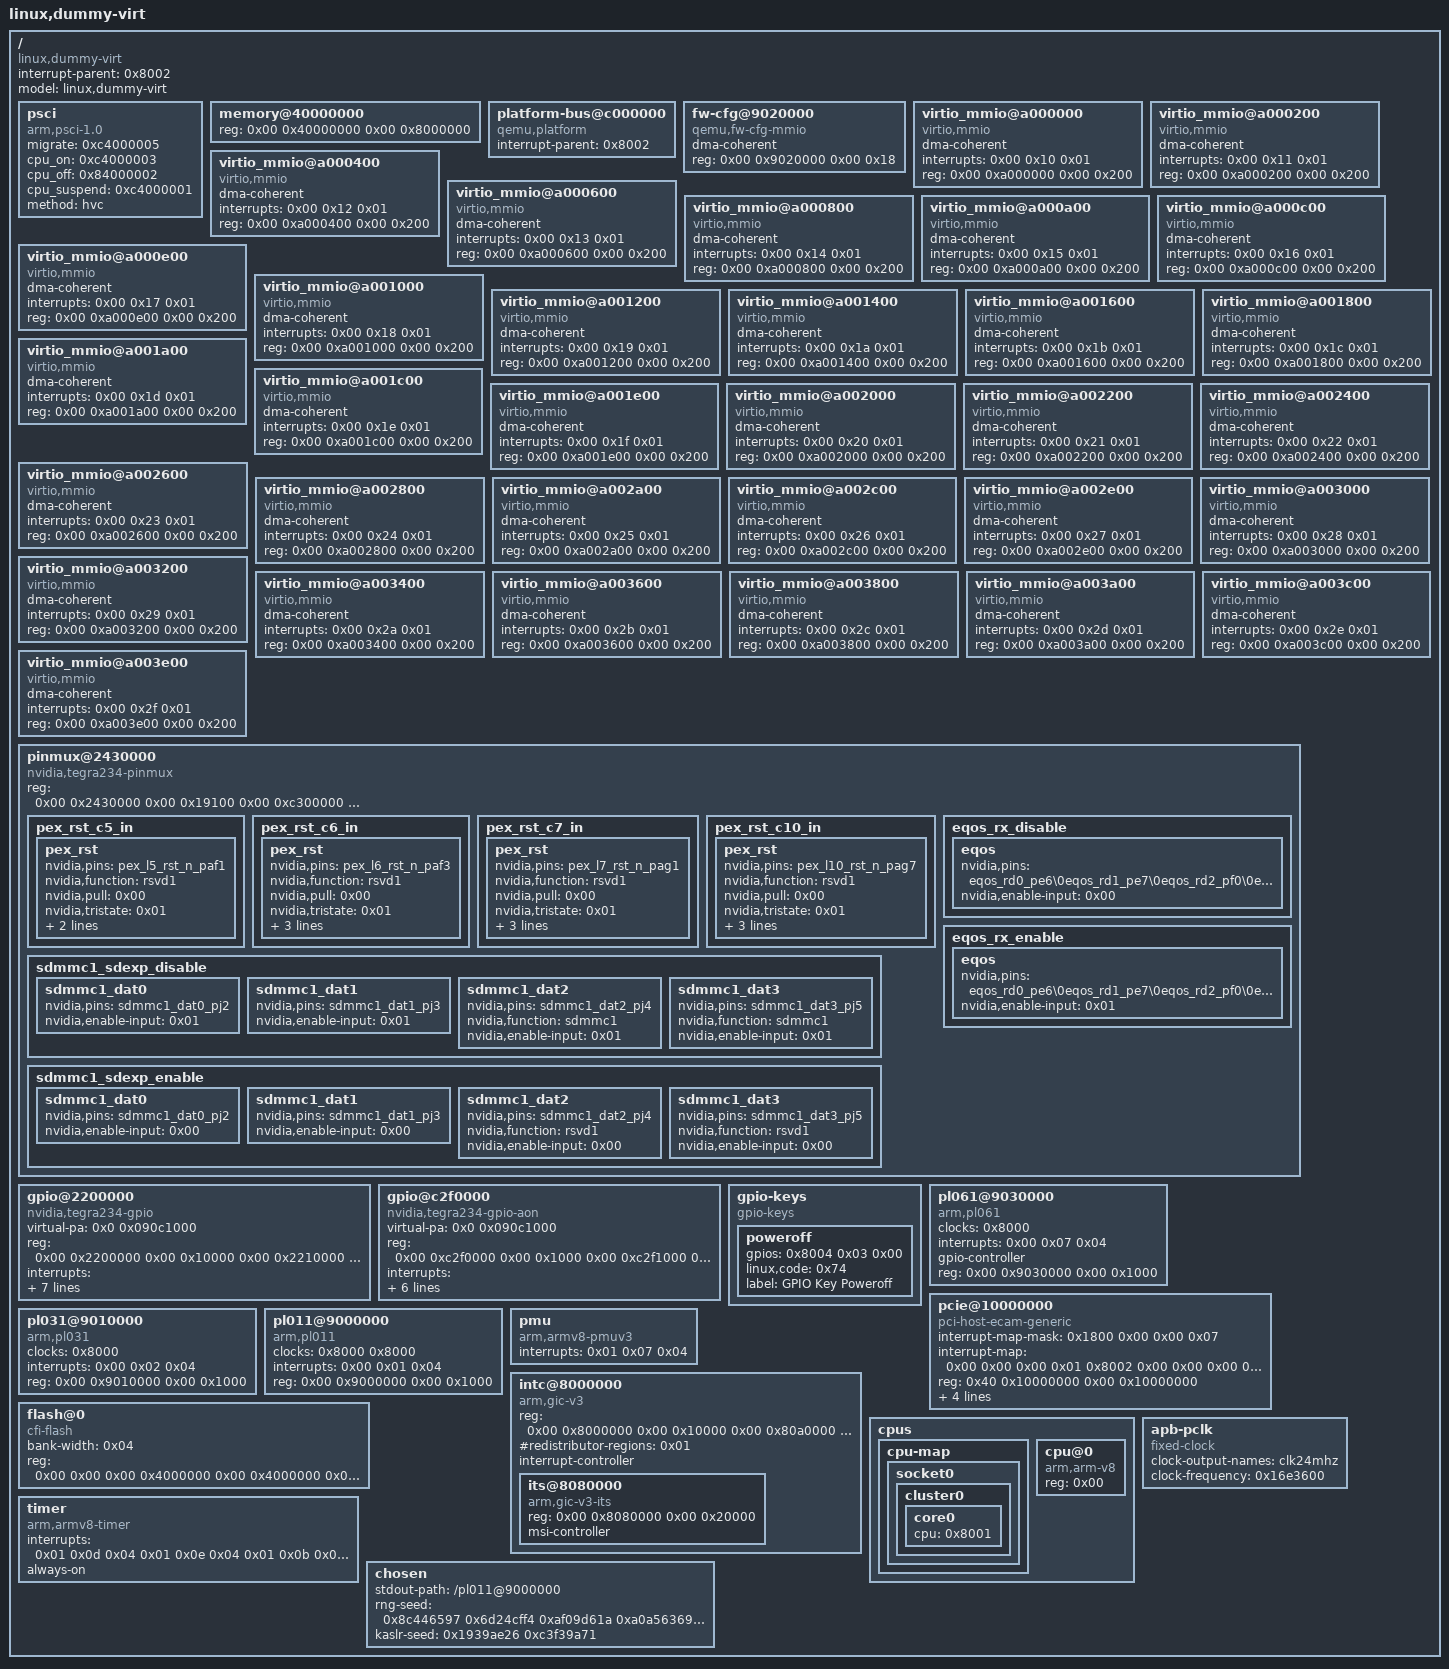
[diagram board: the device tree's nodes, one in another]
/dts-v1/;

/ {
	interrupt-parent = <0x8002>;
	model = "linux,dummy-virt";
	#size-cells = <0x02>;
	#address-cells = <0x02>;
	compatible = "linux,dummy-virt";

	psci {
		migrate = <0xc4000005>;
		cpu_on = <0xc4000003>;
		cpu_off = <0x84000002>;
		cpu_suspend = <0xc4000001>;
		method = "hvc";
		compatible = "arm,psci-1.0\0arm,psci-0.2\0arm,psci";
	};

	memory@40000000 {
		reg = <0x00 0x40000000 0x00 0x8000000>;
		device_type = "memory";
	};

	platform-bus@c000000 {
		interrupt-parent = <0x8002>;
		ranges = <0x00 0x00 0xc000000 0x2000000>;
		#address-cells = <0x01>;
		#size-cells = <0x01>;
		compatible = "qemu,platform\0simple-bus";
	};

	fw-cfg@9020000 {
		dma-coherent;
		reg = <0x00 0x9020000 0x00 0x18>;
		compatible = "qemu,fw-cfg-mmio";
	};

	virtio_mmio@a000000 {
		dma-coherent;
		interrupts = <0x00 0x10 0x01>;
		reg = <0x00 0xa000000 0x00 0x200>;
		compatible = "virtio,mmio";
	};

	virtio_mmio@a000200 {
		dma-coherent;
		interrupts = <0x00 0x11 0x01>;
		reg = <0x00 0xa000200 0x00 0x200>;
		compatible = "virtio,mmio";
	};

	virtio_mmio@a000400 {
		dma-coherent;
		interrupts = <0x00 0x12 0x01>;
		reg = <0x00 0xa000400 0x00 0x200>;
		compatible = "virtio,mmio";
	};

	virtio_mmio@a000600 {
		dma-coherent;
		interrupts = <0x00 0x13 0x01>;
		reg = <0x00 0xa000600 0x00 0x200>;
		compatible = "virtio,mmio";
	};

	virtio_mmio@a000800 {
		dma-coherent;
		interrupts = <0x00 0x14 0x01>;
		reg = <0x00 0xa000800 0x00 0x200>;
		compatible = "virtio,mmio";
	};

	virtio_mmio@a000a00 {
		dma-coherent;
		interrupts = <0x00 0x15 0x01>;
		reg = <0x00 0xa000a00 0x00 0x200>;
		compatible = "virtio,mmio";
	};

	virtio_mmio@a000c00 {
		dma-coherent;
		interrupts = <0x00 0x16 0x01>;
		reg = <0x00 0xa000c00 0x00 0x200>;
		compatible = "virtio,mmio";
	};

	virtio_mmio@a000e00 {
		dma-coherent;
		interrupts = <0x00 0x17 0x01>;
		reg = <0x00 0xa000e00 0x00 0x200>;
		compatible = "virtio,mmio";
	};

	virtio_mmio@a001000 {
		dma-coherent;
		interrupts = <0x00 0x18 0x01>;
		reg = <0x00 0xa001000 0x00 0x200>;
		compatible = "virtio,mmio";
	};

	virtio_mmio@a001200 {
		dma-coherent;
		interrupts = <0x00 0x19 0x01>;
		reg = <0x00 0xa001200 0x00 0x200>;
		compatible = "virtio,mmio";
	};

	virtio_mmio@a001400 {
		dma-coherent;
		interrupts = <0x00 0x1a 0x01>;
		reg = <0x00 0xa001400 0x00 0x200>;
		compatible = "virtio,mmio";
	};

	virtio_mmio@a001600 {
		dma-coherent;
		interrupts = <0x00 0x1b 0x01>;
		reg = <0x00 0xa001600 0x00 0x200>;
		compatible = "virtio,mmio";
	};

	virtio_mmio@a001800 {
		dma-coherent;
		interrupts = <0x00 0x1c 0x01>;
		reg = <0x00 0xa001800 0x00 0x200>;
		compatible = "virtio,mmio";
	};

	virtio_mmio@a001a00 {
		dma-coherent;
		interrupts = <0x00 0x1d 0x01>;
		reg = <0x00 0xa001a00 0x00 0x200>;
		compatible = "virtio,mmio";
	};

	virtio_mmio@a001c00 {
		dma-coherent;
		interrupts = <0x00 0x1e 0x01>;
		reg = <0x00 0xa001c00 0x00 0x200>;
		compatible = "virtio,mmio";
	};

	virtio_mmio@a001e00 {
		dma-coherent;
		interrupts = <0x00 0x1f 0x01>;
		reg = <0x00 0xa001e00 0x00 0x200>;
		compatible = "virtio,mmio";
	};

	virtio_mmio@a002000 {
		dma-coherent;
		interrupts = <0x00 0x20 0x01>;
		reg = <0x00 0xa002000 0x00 0x200>;
		compatible = "virtio,mmio";
	};

	virtio_mmio@a002200 {
		dma-coherent;
		interrupts = <0x00 0x21 0x01>;
		reg = <0x00 0xa002200 0x00 0x200>;
		compatible = "virtio,mmio";
	};

	virtio_mmio@a002400 {
		dma-coherent;
		interrupts = <0x00 0x22 0x01>;
		reg = <0x00 0xa002400 0x00 0x200>;
		compatible = "virtio,mmio";
	};

	virtio_mmio@a002600 {
		dma-coherent;
		interrupts = <0x00 0x23 0x01>;
		reg = <0x00 0xa002600 0x00 0x200>;
		compatible = "virtio,mmio";
	};

	virtio_mmio@a002800 {
		dma-coherent;
		interrupts = <0x00 0x24 0x01>;
		reg = <0x00 0xa002800 0x00 0x200>;
		compatible = "virtio,mmio";
	};

	virtio_mmio@a002a00 {
		dma-coherent;
		interrupts = <0x00 0x25 0x01>;
		reg = <0x00 0xa002a00 0x00 0x200>;
		compatible = "virtio,mmio";
	};

	virtio_mmio@a002c00 {
		dma-coherent;
		interrupts = <0x00 0x26 0x01>;
		reg = <0x00 0xa002c00 0x00 0x200>;
		compatible = "virtio,mmio";
	};

	virtio_mmio@a002e00 {
		dma-coherent;
		interrupts = <0x00 0x27 0x01>;
		reg = <0x00 0xa002e00 0x00 0x200>;
		compatible = "virtio,mmio";
	};

	virtio_mmio@a003000 {
		dma-coherent;
		interrupts = <0x00 0x28 0x01>;
		reg = <0x00 0xa003000 0x00 0x200>;
		compatible = "virtio,mmio";
	};

	virtio_mmio@a003200 {
		dma-coherent;
		interrupts = <0x00 0x29 0x01>;
		reg = <0x00 0xa003200 0x00 0x200>;
		compatible = "virtio,mmio";
	};

	virtio_mmio@a003400 {
		dma-coherent;
		interrupts = <0x00 0x2a 0x01>;
		reg = <0x00 0xa003400 0x00 0x200>;
		compatible = "virtio,mmio";
	};

	virtio_mmio@a003600 {
		dma-coherent;
		interrupts = <0x00 0x2b 0x01>;
		reg = <0x00 0xa003600 0x00 0x200>;
		compatible = "virtio,mmio";
	};

	virtio_mmio@a003800 {
		dma-coherent;
		interrupts = <0x00 0x2c 0x01>;
		reg = <0x00 0xa003800 0x00 0x200>;
		compatible = "virtio,mmio";
	};

	virtio_mmio@a003a00 {
		dma-coherent;
		interrupts = <0x00 0x2d 0x01>;
		reg = <0x00 0xa003a00 0x00 0x200>;
		compatible = "virtio,mmio";
	};

	virtio_mmio@a003c00 {
		dma-coherent;
		interrupts = <0x00 0x2e 0x01>;
		reg = <0x00 0xa003c00 0x00 0x200>;
		compatible = "virtio,mmio";
	};

	virtio_mmio@a003e00 {
		dma-coherent;
		interrupts = <0x00 0x2f 0x01>;
		reg = <0x00 0xa003e00 0x00 0x200>;
		compatible = "virtio,mmio";
	};

  // start of nodes imported from host is here

  /*
  gpio: gpio {
    compatible = "nvidia,tegra234-gpio";
    virtual-pa = <0x0 0x090c1000>;
    status = "okay";
  };
  */

	pinmux@2430000 {
		compatible = "nvidia,tegra234-pinmux";
		reg = <0x00 0x2430000 0x00 0x19100 0x00 0xc300000 0x00 0x4000>;
		#gpio-range-cells = <0x03>;
		status = "okay";
		phandle = <0x2e4>;

		pex_rst_c5_in {
			phandle = <0x0f>;

			pex_rst {
				nvidia,pins = "pex_l5_rst_n_paf1";
				nvidia,function = "rsvd1";
				nvidia,pull = <0x00>;
				nvidia,tristate = <0x01>;
				nvidia,enable-input = <0x01>;
				nvidia,lpdr = <0x00>;
			};
		};

		pex_rst_c6_in {
			phandle = <0x1f>;

			pex_rst {
				nvidia,pins = "pex_l6_rst_n_paf3";
				nvidia,function = "rsvd1";
				nvidia,pull = <0x00>;
				nvidia,tristate = <0x01>;
				nvidia,enable-input = <0x01>;
				nvidia,io-high-voltage = <0x01>;
				nvidia,lpdr = <0x00>;
			};
		};

		pex_rst_c7_in {
			phandle = <0x20>;

			pex_rst {
				nvidia,pins = "pex_l7_rst_n_pag1";
				nvidia,function = "rsvd1";
				nvidia,pull = <0x00>;
				nvidia,tristate = <0x01>;
				nvidia,enable-input = <0x01>;
				nvidia,io-high-voltage = <0x01>;
				nvidia,lpdr = <0x00>;
			};
		};

		pex_rst_c10_in {
			phandle = <0x22>;

			pex_rst {
				nvidia,pins = "pex_l10_rst_n_pag7";
				nvidia,function = "rsvd1";
				nvidia,pull = <0x00>;
				nvidia,tristate = <0x01>;
				nvidia,enable-input = <0x01>;
				nvidia,io-high-voltage = <0x01>;
				nvidia,lpdr = <0x00>;
			};
		};

		eqos_rx_disable {
			phandle = <0x2b>;

			eqos {
				nvidia,pins = "eqos_rd0_pe6\0eqos_rd1_pe7\0eqos_rd2_pf0\0eqos_rd3_pf1\0eqos_rx_ctl_pf2";
				nvidia,enable-input = <0x00>;
			};
		};

		eqos_rx_enable {
			phandle = <0x2c>;

			eqos {
				nvidia,pins = "eqos_rd0_pe6\0eqos_rd1_pe7\0eqos_rd2_pf0\0eqos_rd3_pf1\0eqos_rx_ctl_pf2";
				nvidia,enable-input = <0x01>;
			};
		};

		sdmmc1_sdexp_disable {
			phandle = <0x38>;

			sdmmc1_dat0 {
				nvidia,pins = "sdmmc1_dat0_pj2";
				nvidia,enable-input = <0x01>;
			};

			sdmmc1_dat1 {
				nvidia,pins = "sdmmc1_dat1_pj3";
				nvidia,enable-input = <0x01>;
			};

			sdmmc1_dat2 {
				nvidia,pins = "sdmmc1_dat2_pj4";
				nvidia,function = "sdmmc1";
				nvidia,enable-input = <0x01>;
			};

			sdmmc1_dat3 {
				nvidia,pins = "sdmmc1_dat3_pj5";
				nvidia,function = "sdmmc1";
				nvidia,enable-input = <0x01>;
			};
		};

		sdmmc1_sdexp_enable {
			phandle = <0x37>;

			sdmmc1_dat0 {
				nvidia,pins = "sdmmc1_dat0_pj2";
				nvidia,enable-input = <0x00>;
			};

			sdmmc1_dat1 {
				nvidia,pins = "sdmmc1_dat1_pj3";
				nvidia,enable-input = <0x00>;
			};

			sdmmc1_dat2 {
				nvidia,pins = "sdmmc1_dat2_pj4";
				nvidia,function = "rsvd1";
				nvidia,enable-input = <0x00>;
			};

			sdmmc1_dat3 {
				nvidia,pins = "sdmmc1_dat3_pj5";
				nvidia,function = "rsvd1";
				nvidia,enable-input = <0x00>;
			};
		};
	};

	gpio@2200000 {
		compatible = "nvidia,tegra234-gpio";
    virtual-pa = <0x0 0x090c1000>;
		reg-names = "security\0gpio";
		reg = <0x00 0x2200000 0x00 0x10000 0x00 0x2210000 0x00 0x10000>;
		interrupts = <0x00 0x120 0x04 0x00 0x121 0x04 0x00 0x122 0x04 0x00 0x123 0x04 0x00 0x124 0x04 0x00 0x125 0x04 0x00 0x126 0x04 0x00 0x127 0x04 0x00 0x128 0x04 0x00 0x129 0x04 0x00 0x12a 0x04 0x00 0x12b 0x04 0x00 0x12c 0x04 0x00 0x12d 0x04 0x00 0x12e 0x04 0x00 0x12f 0x04 0x00 0x130 0x04 0x00 0x131 0x04 0x00 0x132 0x04 0x00 0x133 0x04 0x00 0x134 0x04 0x00 0x135 0x04 0x00 0x136 0x04 0x00 0x137 0x04 0x00 0x138 0x04 0x00 0x139 0x04 0x00 0x13a 0x04 0x00 0x13b 0x04 0x00 0x13c 0x04 0x00 0x13d 0x04 0x00 0x13e 0x04 0x00 0x13f 0x04 0x00 0x140 0x04 0x00 0x141 0x04 0x00 0x142 0x04 0x00 0x143 0x04 0x00 0x144 0x04 0x00 0x145 0x04 0x00 0x146 0x04 0x00 0x147 0x04 0x00 0x148 0x04 0x00 0x149 0x04 0x00 0x14a 0x04 0x00 0x14b 0x04 0x00 0x14c 0x04 0x00 0x14d 0x04 0x00 0x14e 0x04 0x00 0x14f 0x04>;
		gpio-controller;
		#gpio-cells = <0x02>;
		// interrupt-controller;
	  // #interrupt-cells = <0x02>;
		gpio-ranges = <0x2e4 0x00 0x00 0x8a 0x2e4 0x8a 0x92 0x1a>;
		status = "okay";
		gpio-line-names = <0x00 0x00 0x00 0x00 0x00 0x00 0x00 0x00 0x00 0x00 0x00 0x00 0x00 0x00 0x4750494f 0x33350000 0x00 0x493253 0x325f5343 0x4c4b0049 0x3253325f 0x444f5554 0x493253 0x325f4449 0x4e004932 0x53325f46 0x53000000 0x00 0x00 0x00 0x00 0x00 0x00 0x00 0x00 0x00 0x4750494f 0x32370000 0x00 0x00 0x475049 0x4f313700 0x00 0x00 0x4d434c 0x4b303500 0x50574d 0x30310000 0x00 0x00 0x00 0x00 0x00 0x00 0x535049 0x315f434c 0x4b005350 0x49315f4d 0x49534f00 0x53504931 0x5f4d4f53 0x49005350 0x49315f43 0x53305f4e 0x535049 0x315f4353 0x315f4e00 0x00>;
		#phandle = <0x14>;
	};

	gpio@c2f0000 {
		compatible = "nvidia,tegra234-gpio-aon";
    virtual-pa = <0x0 0x090c1000>;
		reg-names = "security\0gpio";
		reg = <0x00 0xc2f0000 0x00 0x1000 0x00 0xc2f1000 0x00 0x1000>;
		interrupts = <0x00 0x38 0x04 0x00 0x39 0x04 0x00 0x3a 0x04 0x00 0x3b 0x04>;
		gpio-controller;
		#gpio-cells = <0x02>;
		// interrupt-controller;
		// #interrupt-cells = <0x02>;
		gpio-ranges = <0x2e4 0x00 0x8a 0x08 0x2e4 0x08 0xac 0x18>;
		status = "okay";
		gpio-line-names = "CAN0_DOUT\0CAN0_DIN\0CAN1_DOUT\0CAN1_DIN\0\0\0\0\0GPIO09\0GPIO08\0\0\0\0\0\0\0\0\0\0";
		phandle = <0x3a>;
	};

  __symbols__ {
		pinmux = "/pinmux@2430000";
		tegra_pinctrl = "/pinmux@2430000";
		pex_rst_c5_in_state = "/pinmux@2430000/pex_rst_c5_in";
		pex_rst_c6_in_state = "/pinmux@2430000/pex_rst_c6_in";
		pex_rst_c7_in_state = "/pinmux@2430000/pex_rst_c7_in";
		pex_rst_c10_in_state = "/pinmux@2430000/pex_rst_c10_in";
		eqos_mii_rx_input_state_disable = "/pinmux@2430000/eqos_rx_disable";
		eqos_mii_rx_input_state_enable = "/pinmux@2430000/eqos_rx_enable";
		sdmmc1_sdexp_disable = "/pinmux@2430000/sdmmc1_sdexp_disable";
		sdmmc1_sdexp_enable = "/pinmux@2430000/sdmmc1_sdexp_enable";
  };

  // end of nodes imported from host is here

	gpio-keys {
		compatible = "gpio-keys";

		poweroff {
			gpios = <0x8004 0x03 0x00>;
			linux,code = <0x74>;
			label = "GPIO Key Poweroff";
		};
	};

	pl061@9030000 {
		phandle = <0x8004>;
		clock-names = "apb_pclk";
		clocks = <0x8000>;
		interrupts = <0x00 0x07 0x04>;
		gpio-controller;
		#gpio-cells = <0x02>;
		compatible = "arm,pl061\0arm,primecell";
		reg = <0x00 0x9030000 0x00 0x1000>;
	};

	pcie@10000000 {
		interrupt-map-mask = <0x1800 0x00 0x00 0x07>;
		interrupt-map = <0x00 0x00 0x00 0x01 0x8002 0x00 0x00 0x00 0x03 0x04 0x00 0x00 0x00 0x02 0x8002 0x00 0x00 0x00 0x04 0x04 0x00 0x00 0x00 0x03 0x8002 0x00 0x00 0x00 0x05 0x04 0x00 0x00 0x00 0x04 0x8002 0x00 0x00 0x00 0x06 0x04 0x800 0x00 0x00 0x01 0x8002 0x00 0x00 0x00 0x04 0x04 0x800 0x00 0x00 0x02 0x8002 0x00 0x00 0x00 0x05 0x04 0x800 0x00 0x00 0x03 0x8002 0x00 0x00 0x00 0x06 0x04 0x800 0x00 0x00 0x04 0x8002 0x00 0x00 0x00 0x03 0x04 0x1000 0x00 0x00 0x01 0x8002 0x00 0x00 0x00 0x05 0x04 0x1000 0x00 0x00 0x02 0x8002 0x00 0x00 0x00 0x06 0x04 0x1000 0x00 0x00 0x03 0x8002 0x00 0x00 0x00 0x03 0x04 0x1000 0x00 0x00 0x04 0x8002 0x00 0x00 0x00 0x04 0x04 0x1800 0x00 0x00 0x01 0x8002 0x00 0x00 0x00 0x06 0x04 0x1800 0x00 0x00 0x02 0x8002 0x00 0x00 0x00 0x03 0x04 0x1800 0x00 0x00 0x03 0x8002 0x00 0x00 0x00 0x04 0x04 0x1800 0x00 0x00 0x04 0x8002 0x00 0x00 0x00 0x05 0x04>;
		#interrupt-cells = <0x01>;
		ranges = <0x1000000 0x00 0x00 0x00 0x3eff0000 0x00 0x10000 0x2000000 0x00 0x10000000 0x00 0x10000000 0x00 0x2eff0000 0x3000000 0x80 0x00 0x80 0x00 0x80 0x00>;
		reg = <0x40 0x10000000 0x00 0x10000000>;
		msi-map = <0x00 0x8003 0x00 0x10000>;
		dma-coherent;
		bus-range = <0x00 0xff>;
		linux,pci-domain = <0x00>;
		#size-cells = <0x02>;
		#address-cells = <0x03>;
		device_type = "pci";
		compatible = "pci-host-ecam-generic";
	};

	pl031@9010000 {
		clock-names = "apb_pclk";
		clocks = <0x8000>;
		interrupts = <0x00 0x02 0x04>;
		reg = <0x00 0x9010000 0x00 0x1000>;
		compatible = "arm,pl031\0arm,primecell";
	};

	pl011@9000000 {
		clock-names = "uartclk\0apb_pclk";
		clocks = <0x8000 0x8000>;
		interrupts = <0x00 0x01 0x04>;
		reg = <0x00 0x9000000 0x00 0x1000>;
		compatible = "arm,pl011\0arm,primecell";
	};

	pmu {
		interrupts = <0x01 0x07 0x04>;
		compatible = "arm,armv8-pmuv3";
	};

	intc@8000000 {
		phandle = <0x8002>;
		reg = <0x00 0x8000000 0x00 0x10000 0x00 0x80a0000 0x00 0xf60000>;
		#redistributor-regions = <0x01>;
		compatible = "arm,gic-v3";
		ranges;
		#size-cells = <0x02>;
		#address-cells = <0x02>;
		interrupt-controller;
		#interrupt-cells = <0x03>;

		its@8080000 {
			phandle = <0x8003>;
			reg = <0x00 0x8080000 0x00 0x20000>;
			#msi-cells = <0x01>;
			msi-controller;
			compatible = "arm,gic-v3-its";
		};
	};

	flash@0 {
		bank-width = <0x04>;
		reg = <0x00 0x00 0x00 0x4000000 0x00 0x4000000 0x00 0x4000000>;
		compatible = "cfi-flash";
	};

	cpus {
		#size-cells = <0x00>;
		#address-cells = <0x01>;

		cpu-map {

			socket0 {

				cluster0 {

					core0 {
						cpu = <0x8001>;
					};
				};
			};
		};

		cpu@0 {
			phandle = <0x8001>;
			reg = <0x00>;
			compatible = "arm,arm-v8";
			device_type = "cpu";
		};
	};

	timer {
		interrupts = <0x01 0x0d 0x04 0x01 0x0e 0x04 0x01 0x0b 0x04 0x01 0x0a 0x04>;
		always-on;
		compatible = "arm,armv8-timer\0arm,armv7-timer";
	};

	apb-pclk {
		phandle = <0x8000>;
		clock-output-names = "clk24mhz";
		clock-frequency = <0x16e3600>;
		#clock-cells = <0x00>;
		compatible = "fixed-clock";
	};

	chosen {
		stdout-path = "/pl011@9000000";
		rng-seed = <0x8c446597 0x6d24cff4 0xaf09d61a 0xa0a56369 0x924973b8 0x9fd6f4bb 0x4fe9099f 0x454a3b2c>;
		kaslr-seed = <0x1939ae26 0xc3f39a71>;
	};
};
